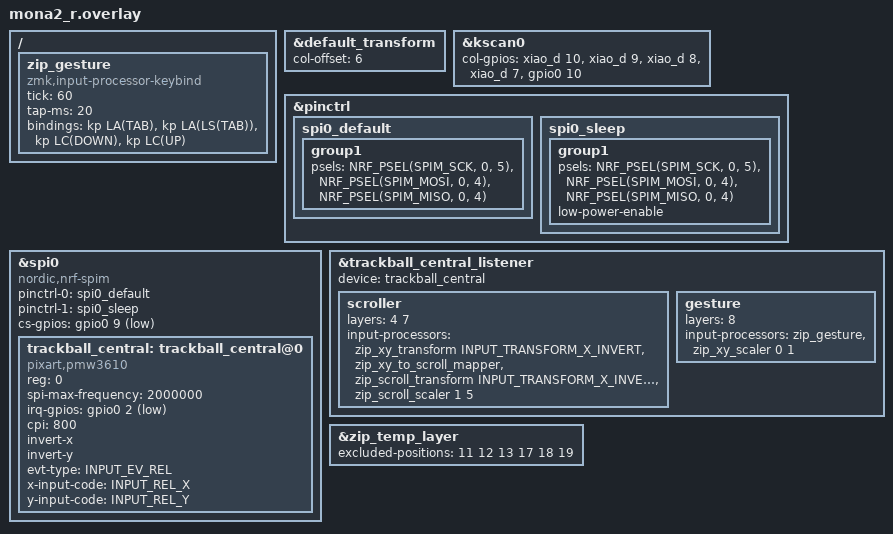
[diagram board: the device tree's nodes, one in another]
#include "mona2.dtsi"
#include <input/processors.dtsi>
#include <zephyr/dt-bindings/input/input-event-codes.h>


&default_transform {
    col-offset = <6>;
};

&kscan0 {
        col-gpios
            = <&xiao_d 10 GPIO_ACTIVE_HIGH>
            , <&xiao_d 9 GPIO_ACTIVE_HIGH> 
            , <&xiao_d 8 GPIO_ACTIVE_HIGH> 
            , <&xiao_d 7 GPIO_ACTIVE_HIGH> 
            , <&gpio0 10 GPIO_ACTIVE_HIGH>
            ;
};


&pinctrl {
    spi0_default: spi0_default {    //通常時(SPI通信中)のピン構成
        group1 {
            psels = <NRF_PSEL(SPIM_SCK, 0, 5)>, //P0.05を指定(SCLK)
                <NRF_PSEL(SPIM_MOSI, 0, 4)>,    //P0.04を指定(SDIOだからMOSI,MISO両方の役割を担う)
                <NRF_PSEL(SPIM_MISO, 0, 4)>;
        };
    };

    spi0_sleep: spi0_sleep {    //スリープ時のピン構成(省電力)
        group1 {
            psels = <NRF_PSEL(SPIM_SCK, 0, 5)>,
                <NRF_PSEL(SPIM_MOSI, 0, 4)>,
                <NRF_PSEL(SPIM_MISO, 0, 4)>;
            low-power-enable;
        };
    };
};


&spi0 {
    status = "okay";
    compatible = "nordic,nrf-spim"; //マイコンがnRFシリーズ
    pinctrl-0 = <&spi0_default>;
    pinctrl-1 = <&spi0_sleep>;
    pinctrl-names = "default", "sleep";
    cs-gpios = <&gpio0 9 GPIO_ACTIVE_LOW>;  //P0.09を指定(CS)

    trackball_central: trackball_central@0 {
        status = "okay";
        compatible = "pixart,pmw3610";  //トラボセンサ用のドライバとバインド
        reg = <0>;
        spi-max-frequency = <2000000>;
        irq-gpios = <&gpio0 2 (GPIO_ACTIVE_LOW | GPIO_PULL_UP)>; //P0.02を指定(MOTION)
        cpi = <800>;
        //swap-xy;
        invert-x; //COROPIT版ではコメントアウトを外す
        invert-y; //COROPIT版ではコメントアウトを外す
        evt-type = <INPUT_EV_REL>;
        x-input-code = <INPUT_REL_X>;
        y-input-code = <INPUT_REL_Y>;
    };
};


// Overrides for the input listener node
&trackball_central_listener {
    status = "okay";
    device = <&trackball_central>;

    scroller {
        layers = <4 7>;    // 4=NAVホールド中 / 7=SCROLL(トグル用、&tog 7を配置すると有効)
        input-processors =
            // <&zip_xy_transform INPUT_TRANSFORM_XY_SWAP>,        //X軸とY軸の入れ替え
            <&zip_xy_transform INPUT_TRANSFORM_X_INVERT>,       //X軸反転
            <&zip_xy_to_scroll_mapper>,                         //スクロールモードに変更
            <&zip_scroll_transform INPUT_TRANSFORM_X_INVERT>,   //スクロールのX軸反転
            <&zip_scroll_scaler 1 5>;                           //スクロール量を1/4倍
    };

};

// オートマウスレイヤーの除外キー設定：
// 以下の位置のキー(MOUSEレイヤーのクリック類)を押してもAMLを維持し、
// それ以外のキーを押すと即座に通常レイヤーへ復帰する
// 11/12/13 = 左手 MB3/MB2/MB1, 17/18/19 = 右手 LCLK/MCLK/RCLK
&zip_temp_layer {
    excluded-positions = <11 12 13 17 18 19>;
};

// ジェスチャ用プロセッサ：GESTUREレイヤー(8)中のボール移動をキー入力に変換
// bindings順 = 右, 左, 下, 上 (現状はAeroSpace用プレースホルダ。変更はこの4つを書き換え)
// 右=次ワークスペース / 左=前ワークスペース / 下=アプリExposé / 上=Mission Control
/ {
    zip_gesture: zip_gesture {
        compatible = "zmk,input-processor-keybind";
        #input-processor-cells = <0>;
        tick = <60>;      // 1発火に必要な移動量。大きいほど「大振りフリック」向き
        tap-ms = <20>;
        bindings = <&kp LA(TAB)>, <&kp LA(LS(TAB))>, <&kp LC(DOWN)>, <&kp LC(UP)>;
    };
};

&trackball_central_listener {
    gesture {
        layers = <8>;    // GESTURE (&mo 8 を配置すると有効)
        input-processors = <&zip_gesture>, <&zip_xy_scaler 0 1>;    // scaler 0倍でカーソル移動を殺す
    };
};
